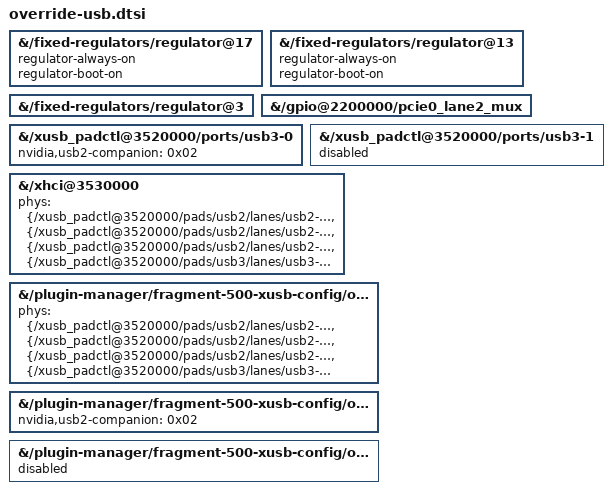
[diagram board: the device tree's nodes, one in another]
/* Auvidea J106 carrier - USB VBUS fix (appended to decompiled stock R32.7.6 c03 DTB)
 *
 * Stock gates vdd_usb2_5v with an I2C GPIO expander (ti,tca9539 @0x74) that is
 * absent on the J106 carrier. The regulator therefore never enables and
 * xusb_padctl defers forever (-EPROBE_DEFER/-517) -> all USB dead.
 * Drop the expander gpio and force the fixed regulator always-on so no consumer
 * (port vbus-supply or padctl vbus-2-supply) can defer on the missing chip.
 */
&{/fixed-regulators/regulator@17} {
	/delete-property/ gpio;
	regulator-always-on;
	regulator-boot-on;
};

/* Carrier FAN regulator — same absent-expander issue as USB above.
 *
 * vdd-fan (regulator@13) is also gated by a GPIO on the devkit's pca9539 I2C expander
 * (the same chip, absent on the J106/M110). So the regulator never registers →
 * "FAN: coudln't get the regulator" → the `pwm-fan` driver fails to probe (stays
 * unbound) → no PWM control interface → the fan runs uncontrolled at full speed.
 * Same fix: drop the expander gpio, force the regulator always-on. Then pwm-fan probes,
 * registers as a cooling device under thermal-fan-est, and the kernel ramps the fan with
 * temperature (off when cool, spins up under load) — as on TX1. Verified: at ~33 °C the
 * fan is now OFF (target_pwm=0, RPM=0) instead of always‑on.
 */
&{/fixed-regulators/regulator@13} {
	/delete-property/ gpio;
	regulator-always-on;
	regulator-boot-on;
};

/* Carrier HDMI 5V regulator — same absent-expander gate.
 *
 * vdd-hdmi (regulator@3) is gated by the same expander gpio. It is already marked
 * always-on, but the fixed-regulator driver still defers trying to get the absent
 * expander's GPIO, so the nvdisplay HDMI driver's regulator_get returns -517
 * ("tegradc nvdisplay: couldn't get regulator vdd_hdmi_5v0, -517"). Drop the expander
 * gpio (it's already always-on) so the regulator registers immediately and HDMI hot-plug
 * works. (The residual "tegra_hdmi_tmds_range_read failed" is just the EDID read with no
 * monitor attached — benign.)
 */
&{/fixed-regulators/regulator@3} {
	/delete-property/ gpio;
};

/* Note on the micro-USB / OTG port (USB0 → M110 connector J17):
 *
 * We deliberately leave usb2-0 as stock `mode="otg"`. The Linux device-mode gadget
 * (/dev/ttyACM0 + 192.168.55.1) does NOT work on the M110 J17 — it is a host-leaning
 * port (USB0_ID floats → host, USB0_VBUS tied to the M110's own 5V out), so xudc never
 * sees the host's VBUS (dmesg: `xudc vbus state: 0`, `extcon@1: USB_HOST=1`). Forcing
 * `mode="device"` only binds an offline gadget and prevents J17 from acting as a USB
 * host — no benefit — so it is NOT done. Recovery/flashing over J17 works regardless
 * (bootrom-driven RCM; verified: host sees 0955:7c18). See README §7 + tools/.
 */



/* Carrier USB 3.0 on J3 (silkscreen USB2) — one SS lane, steered to PEX1.
 *
 * TX2 module balls (OEM Design Guide pin matrix, row 41-43):
 *   H41/H42 = PEX1_RX, E41/E42 = PEX1_TX          -> J106 J3 pins 6/7, 9/10
 *   F43/F44 = USB_SS0_RX, C43/C44 = USB_SS0_TX    -> J106 J2 pins 6/7, 9/10
 *   SATA is E45/E46/G45/G46 (the tech-ref "SATA by default" note is TX1-only).
 * Both ball groups are fed by UPHY lane 0 = usb3-0 through a mux ON THE MODULE,
 * selected by QSPI_IO2 = TEGRA_MAIN_GPIO(R,3) = gpio 459: low -> PEX1 (J3),
 * high/float -> USB_SS0 (J2). Stock ODMDATA 0x1090000 owns lane 0 only, so
 * exactly one of J2/J3 can be SuperSpeed. J3 is chosen because its D+/D-
 * (B42/B43 = usb2-2 = usb 1-3) is the pair that enumerates on this board, and
 * Auvidea's own J90/J120 DTBs pair usb3-0 with usb2-2 as well.
 *
 * Verified live 2026-09-17: gpio 459 unclaimed at boot; driving it low with an
 * RTL9210 enclosure on J3 makes the enclosure stop enumerating even at HS
 * (it senses a SuperSpeed host and stalls in training), driving it high brings
 * HS back. So the SS pairs do reach J3 through the cable; they are crossed.
 * J106 puts module RX on pins 6/7, which an OTG-style micro-B->A-female
 * adapter routes to StdA_SSTX -> device RX. Use a micro-B->A-MALE (HDD) cable
 * plus an A-A female coupler, or swap 6/7 <-> 9/10 in the adapter.
 *
 * VBUS/oc-pin left stock (as in j106auv): usb2-2 sits on the always-on
 * vdd-usb2-5v; forcing vdd-usb1-5v on only logs `port 1 over-current`.
 * usb3-1 stays disabled (no second XUSB lane; do not flash 0x3090000).
 *
 * Apply twice: fragment-500-xusb-config matches this SKU and rewrites
 * companions + the xhci phy list at boot.
 */
&{/gpio@2200000/pcie0_lane2_mux} {
	status = "okay";
};

&{/xusb_padctl@3520000/ports/usb3-0} {
	status = "okay";
	nvidia,usb2-companion = <0x02>;
};

&{/xusb_padctl@3520000/ports/usb3-1} {
	status = "disabled";
};

&{/xhci@3530000} {
	phys = <&{/xusb_padctl@3520000/pads/usb2/lanes/usb2-0}
		&{/xusb_padctl@3520000/pads/usb2/lanes/usb2-1}
		&{/xusb_padctl@3520000/pads/usb2/lanes/usb2-2}
		&{/xusb_padctl@3520000/pads/usb3/lanes/usb3-0}>;
	phy-names = "usb2-0", "usb2-1", "usb2-2", "usb3-0";
};

&{/plugin-manager/fragment-500-xusb-config/override@0/_overlay_} {
	phys = <&{/xusb_padctl@3520000/pads/usb2/lanes/usb2-0}
		&{/xusb_padctl@3520000/pads/usb2/lanes/usb2-1}
		&{/xusb_padctl@3520000/pads/usb2/lanes/usb2-2}
		&{/xusb_padctl@3520000/pads/usb3/lanes/usb3-0}>;
	phy-names = "usb2-0", "usb2-1", "usb2-2", "usb3-0";
};

&{/plugin-manager/fragment-500-xusb-config/override@1/_overlay_/ports/usb3-0} {
	status = "okay";
	nvidia,usb2-companion = <0x02>;
};

&{/plugin-manager/fragment-500-xusb-config/override@1/_overlay_/ports/usb3-1} {
	status = "disabled";
};
